VERSION ""

NS_ :

BS_:

BU_: XXX DSU HCU EPS IPAS

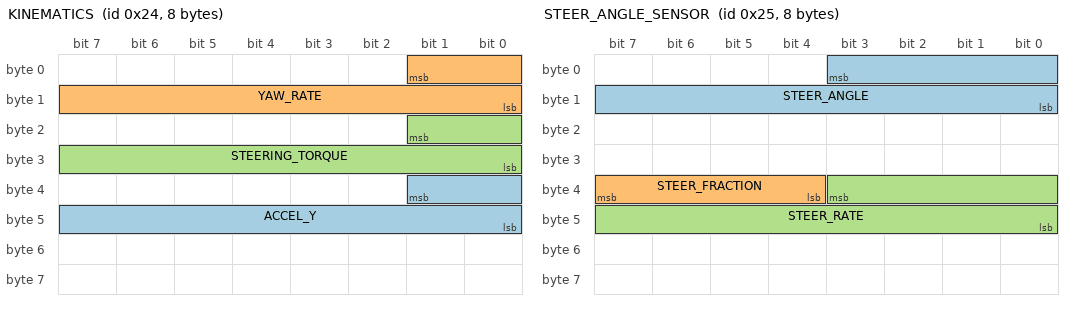
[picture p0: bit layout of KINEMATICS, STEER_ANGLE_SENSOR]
BO_ 36 KINEMATICS: 8 XXX
 SG_ ACCEL_Y : 33|10@0+ (1,-512) [0|65535] "" XXX
 SG_ YAW_RATE : 1|10@0+ (1,-512) [0|65535] "" XXX
 SG_ STEERING_TORQUE : 17|10@0+ (1,-512) [0|65535] "" XXX

BO_ 37 STEER_ANGLE_SENSOR: 8 XXX
 SG_ STEER_ANGLE : 3|12@0- (1.5,0) [-500|500] "deg" XXX
 SG_ STEER_FRACTION : 39|4@0- (0.1,0) [-0.7|0.7] "deg" XXX
 SG_ STEER_RATE : 35|12@0- (1,0) [-2000|2000] "deg/s" XXX

BO_ 166 BRAKE: 8 XXX
 SG_ BRAKE_AMOUNT : 7|8@0+ (1,0) [0|255] "" XXX
 SG_ BRAKE_PEDAL : 23|8@0+ (1,0) [0|255] "" XXX

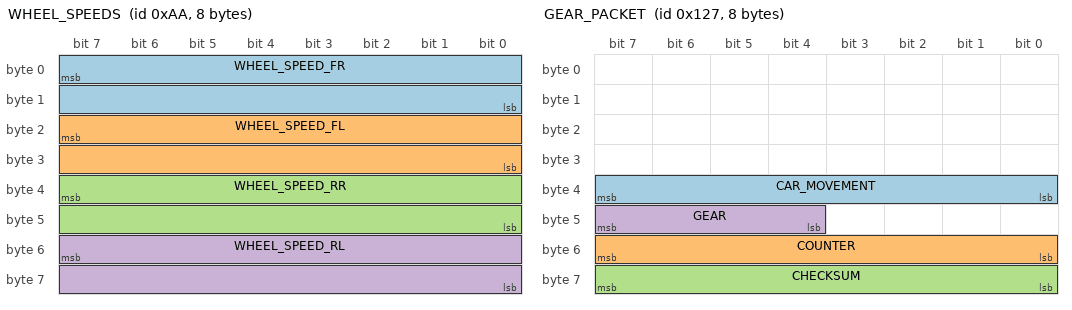
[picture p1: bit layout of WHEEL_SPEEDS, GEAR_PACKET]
BO_ 170 WHEEL_SPEEDS: 8 XXX
 SG_ WHEEL_SPEED_FR : 7|16@0+ (0.01,-67.67) [0|250] "kph" XXX
 SG_ WHEEL_SPEED_FL : 23|16@0+ (0.01,-67.67) [0|250] "kph" XXX
 SG_ WHEEL_SPEED_RR : 39|16@0+ (0.01,-67.67) [0|250] "kph" XXX
 SG_ WHEEL_SPEED_RL : 55|16@0+ (0.01,-67.67) [0|250] "kph" XXX

BO_ 176 WHEEL_SPEED_1: 8 XXX
 SG_ NEW_SIGNAL_3 : 43|4@0+ (1,0) [0|15] "" XXX
 SG_ wheel_1 : 7|16@0+ (1,0) [0|1] "" XXX
 SG_ wheel_2 : 23|16@0+ (1,0) [0|3] "" XXX

BO_ 178 WHEEL_SPEED_2: 8 XXX
 SG_ NEW_SIGNAL_3 : 47|8@0+ (1,0) [0|65535] "" XXX
 SG_ WHEEL_3 : 7|16@0+ (1,0) [0|65535] "" XXX
 SG_ wheel_4 : 23|16@0+ (1,0) [0|65535] "" XXX

BO_ 180 SPEED: 8 XXX
 SG_ CHECKSUM : 63|8@0+ (1,0) [0|255] "" XXX
 SG_ ENCODER : 39|8@0+ (1,0) [0|255] "" XXX
 SG_ SPEED : 47|16@0+ (0.01,0) [0|250] "kph" XXX

BO_ 295 GEAR_PACKET: 8 XXX
 SG_ CAR_MOVEMENT : 39|8@0- (1,0) [0|255] "" XXX
 SG_ COUNTER : 55|8@0+ (1,0) [0|255] "" XXX
 SG_ CHECKSUM : 63|8@0+ (1,0) [0|255] "" XXX
 SG_ GEAR : 47|4@0+ (1,0) [0|15] "" XXX

BO_ 466 PCM_CRUISE: 8 XXX
 SG_ GAS_RELEASED : 4|1@0+ (1,0) [0|1] "" XXX
 SG_ CRUISE_STATE : 55|4@0+ (1,0) [0|15] "" XXX

BO_ 467 PCM_CRUISE_2: 8 XXX
 SG_ MAIN_ON : 15|1@0+ (1,0) [0|1] "" XXX
 SG_ SET_SPEED : 23|8@0+ (1,0) [0|255] "kph" XXX

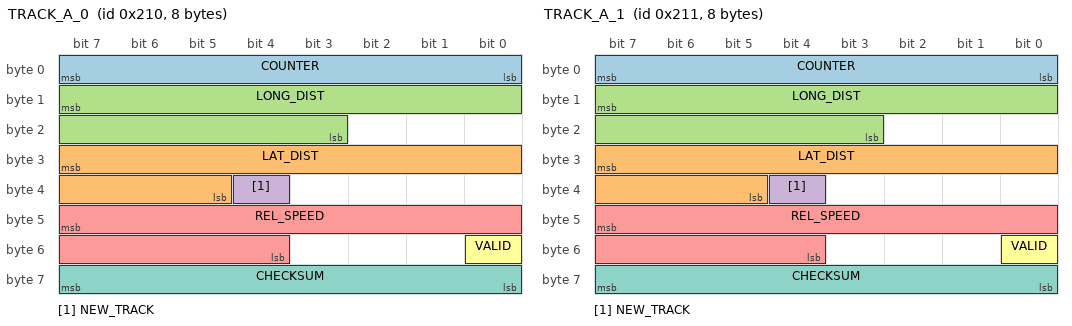
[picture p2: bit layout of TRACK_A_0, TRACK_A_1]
BO_ 528 TRACK_A_0: 8 XXX
 SG_ COUNTER : 7|8@0+ (1,0) [0|255] "" XXX
 SG_ LAT_DIST : 31|11@0- (0.04,0) [-50|50] "m" XXX
 SG_ LONG_DIST : 15|13@0+ (0.04,0) [0|300] "m" XXX
 SG_ NEW_TRACK : 36|1@0+ (1,0) [0|1] "" XXX
 SG_ REL_SPEED : 47|12@0- (0.025,0) [-100|100] "m/s" XXX
 SG_ VALID : 48|1@0+ (1,0) [0|1] "" XXX
 SG_ CHECKSUM : 63|8@0+ (1,0) [0|255] "" XXX

BO_ 529 TRACK_A_1: 8 XXX
 SG_ COUNTER : 7|8@0+ (1,0) [0|255] "" XXX
 SG_ LAT_DIST : 31|11@0- (0.04,0) [-50|50] "m" XXX
 SG_ LONG_DIST : 15|13@0+ (0.04,0) [0|300] "m" XXX
 SG_ NEW_TRACK : 36|1@0+ (1,0) [0|1] "" XXX
 SG_ REL_SPEED : 47|12@0- (0.025,0) [-100|100] "m/s" XXX
 SG_ VALID : 48|1@0+ (1,0) [0|1] "" XXX
 SG_ CHECKSUM : 63|8@0+ (1,0) [0|255] "" XXX

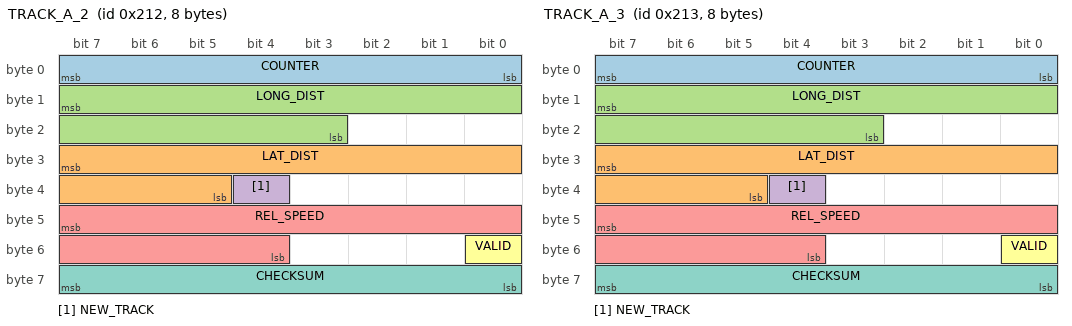
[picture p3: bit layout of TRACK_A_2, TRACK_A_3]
BO_ 530 TRACK_A_2: 8 XXX
 SG_ COUNTER : 7|8@0+ (1,0) [0|255] "" XXX
 SG_ LAT_DIST : 31|11@0- (0.04,0) [-50|50] "m" XXX
 SG_ LONG_DIST : 15|13@0+ (0.04,0) [0|300] "m" XXX
 SG_ NEW_TRACK : 36|1@0+ (1,0) [0|1] "" XXX
 SG_ REL_SPEED : 47|12@0- (0.025,0) [-100|100] "m/s" XXX
 SG_ VALID : 48|1@0+ (1,0) [0|1] "" XXX
 SG_ CHECKSUM : 63|8@0+ (1,0) [0|255] "" XXX

BO_ 531 TRACK_A_3: 8 XXX
 SG_ COUNTER : 7|8@0+ (1,0) [0|255] "" XXX
 SG_ LAT_DIST : 31|11@0- (0.04,0) [-50|50] "m" XXX
 SG_ LONG_DIST : 15|13@0+ (0.04,0) [0|300] "m" XXX
 SG_ NEW_TRACK : 36|1@0+ (1,0) [0|1] "" XXX
 SG_ REL_SPEED : 47|12@0- (0.025,0) [-100|100] "m/s" XXX
 SG_ VALID : 48|1@0+ (1,0) [0|1] "" XXX
 SG_ CHECKSUM : 63|8@0+ (1,0) [0|255] "" XXX

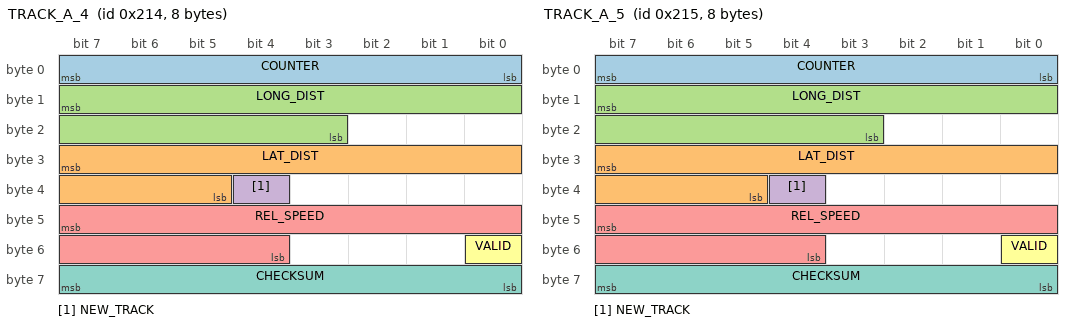
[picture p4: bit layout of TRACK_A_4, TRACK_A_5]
BO_ 532 TRACK_A_4: 8 XXX
 SG_ COUNTER : 7|8@0+ (1,0) [0|255] "" XXX
 SG_ LAT_DIST : 31|11@0- (0.04,0) [-50|50] "m" XXX
 SG_ LONG_DIST : 15|13@0+ (0.04,0) [0|300] "m" XXX
 SG_ NEW_TRACK : 36|1@0+ (1,0) [0|1] "" XXX
 SG_ REL_SPEED : 47|12@0- (0.025,0) [-100|100] "m/s" XXX
 SG_ VALID : 48|1@0+ (1,0) [0|1] "" XXX
 SG_ CHECKSUM : 63|8@0+ (1,0) [0|255] "" XXX

BO_ 533 TRACK_A_5: 8 XXX
 SG_ COUNTER : 7|8@0+ (1,0) [0|255] "" XXX
 SG_ LAT_DIST : 31|11@0- (0.04,0) [-50|50] "m" XXX
 SG_ LONG_DIST : 15|13@0+ (0.04,0) [0|300] "m" XXX
 SG_ NEW_TRACK : 36|1@0+ (1,0) [0|1] "" XXX
 SG_ REL_SPEED : 47|12@0- (0.025,0) [-100|100] "m/s" XXX
 SG_ VALID : 48|1@0+ (1,0) [0|1] "" XXX
 SG_ CHECKSUM : 63|8@0+ (1,0) [0|255] "" XXX

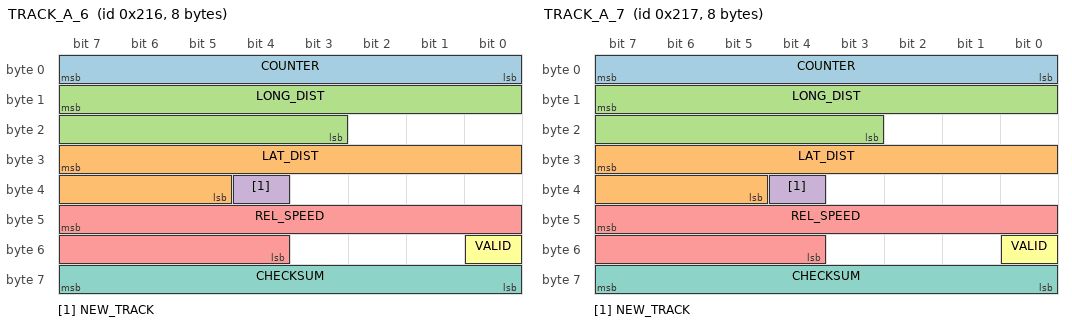
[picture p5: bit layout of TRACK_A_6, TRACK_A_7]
BO_ 534 TRACK_A_6: 8 XXX
 SG_ COUNTER : 7|8@0+ (1,0) [0|255] "" XXX
 SG_ LAT_DIST : 31|11@0- (0.04,0) [-50|50] "m" XXX
 SG_ LONG_DIST : 15|13@0+ (0.04,0) [0|300] "m" XXX
 SG_ NEW_TRACK : 36|1@0+ (1,0) [0|1] "" XXX
 SG_ REL_SPEED : 47|12@0- (0.025,0) [-100|100] "m/s" XXX
 SG_ VALID : 48|1@0+ (1,0) [0|1] "" XXX
 SG_ CHECKSUM : 63|8@0+ (1,0) [0|255] "" XXX

BO_ 535 TRACK_A_7: 8 XXX
 SG_ COUNTER : 7|8@0+ (1,0) [0|255] "" XXX
 SG_ LAT_DIST : 31|11@0- (0.04,0) [-50|50] "m" XXX
 SG_ LONG_DIST : 15|13@0+ (0.04,0) [0|300] "m" XXX
 SG_ NEW_TRACK : 36|1@0+ (1,0) [0|1] "" XXX
 SG_ REL_SPEED : 47|12@0- (0.025,0) [-100|100] "m/s" XXX
 SG_ VALID : 48|1@0+ (1,0) [0|1] "" XXX
 SG_ CHECKSUM : 63|8@0+ (1,0) [0|255] "" XXX

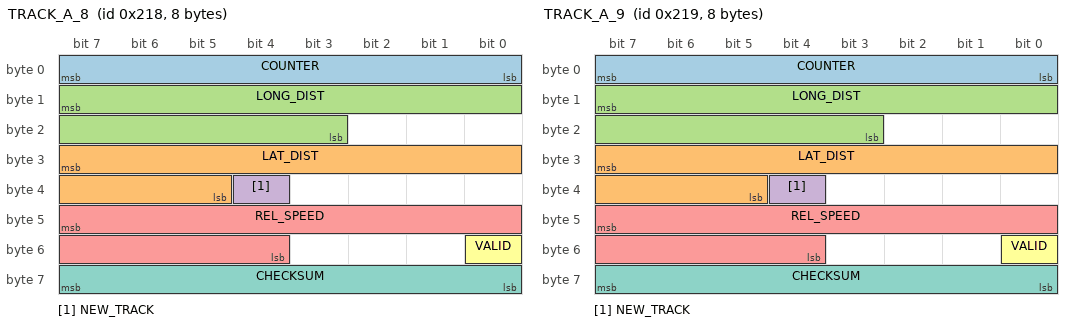
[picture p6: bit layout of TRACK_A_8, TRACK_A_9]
BO_ 536 TRACK_A_8: 8 XXX
 SG_ COUNTER : 7|8@0+ (1,0) [0|255] "" XXX
 SG_ LAT_DIST : 31|11@0- (0.04,0) [-50|50] "m" XXX
 SG_ LONG_DIST : 15|13@0+ (0.04,0) [0|300] "m" XXX
 SG_ NEW_TRACK : 36|1@0+ (1,0) [0|1] "" XXX
 SG_ REL_SPEED : 47|12@0- (0.025,0) [-100|100] "m/s" XXX
 SG_ VALID : 48|1@0+ (1,0) [0|1] "" XXX
 SG_ CHECKSUM : 63|8@0+ (1,0) [0|255] "" XXX

BO_ 537 TRACK_A_9: 8 XXX
 SG_ COUNTER : 7|8@0+ (1,0) [0|255] "" XXX
 SG_ LAT_DIST : 31|11@0- (0.04,0) [-50|50] "m" XXX
 SG_ LONG_DIST : 15|13@0+ (0.04,0) [0|300] "m" XXX
 SG_ NEW_TRACK : 36|1@0+ (1,0) [0|1] "" XXX
 SG_ REL_SPEED : 47|12@0- (0.025,0) [-100|100] "m/s" XXX
 SG_ VALID : 48|1@0+ (1,0) [0|1] "" XXX
 SG_ CHECKSUM : 63|8@0+ (1,0) [0|255] "" XXX

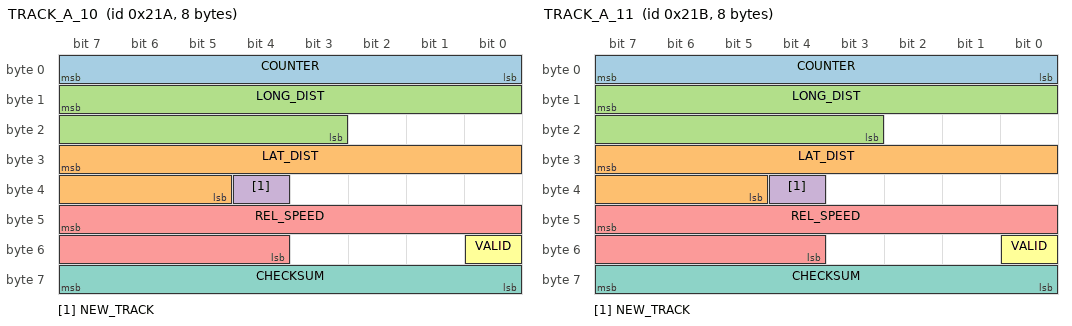
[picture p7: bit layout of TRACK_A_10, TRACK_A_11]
BO_ 538 TRACK_A_10: 8 XXX
 SG_ COUNTER : 7|8@0+ (1,0) [0|255] "" XXX
 SG_ LAT_DIST : 31|11@0- (0.04,0) [-50|50] "m" XXX
 SG_ LONG_DIST : 15|13@0+ (0.04,0) [0|300] "m" XXX
 SG_ NEW_TRACK : 36|1@0+ (1,0) [0|1] "" XXX
 SG_ REL_SPEED : 47|12@0- (0.025,0) [-100|100] "m/s" XXX
 SG_ VALID : 48|1@0+ (1,0) [0|1] "" XXX
 SG_ CHECKSUM : 63|8@0+ (1,0) [0|255] "" XXX

BO_ 539 TRACK_A_11: 8 XXX
 SG_ COUNTER : 7|8@0+ (1,0) [0|255] "" XXX
 SG_ LAT_DIST : 31|11@0- (0.04,0) [-50|50] "m" XXX
 SG_ LONG_DIST : 15|13@0+ (0.04,0) [0|300] "m" XXX
 SG_ NEW_TRACK : 36|1@0+ (1,0) [0|1] "" XXX
 SG_ REL_SPEED : 47|12@0- (0.025,0) [-100|100] "m/s" XXX
 SG_ VALID : 48|1@0+ (1,0) [0|1] "" XXX
 SG_ CHECKSUM : 63|8@0+ (1,0) [0|255] "" XXX

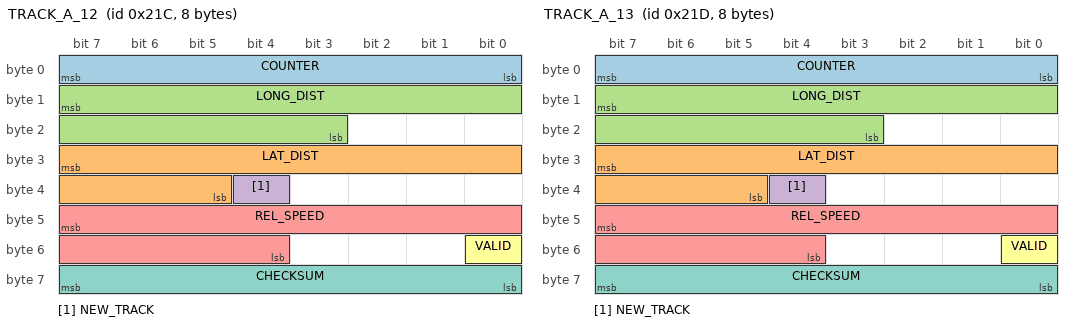
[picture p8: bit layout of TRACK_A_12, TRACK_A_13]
BO_ 540 TRACK_A_12: 8 XXX
 SG_ COUNTER : 7|8@0+ (1,0) [0|255] "" XXX
 SG_ LAT_DIST : 31|11@0- (0.04,0) [-50|50] "m" XXX
 SG_ LONG_DIST : 15|13@0+ (0.04,0) [0|300] "m" XXX
 SG_ NEW_TRACK : 36|1@0+ (1,0) [0|1] "" XXX
 SG_ REL_SPEED : 47|12@0- (0.025,0) [-100|100] "m/s" XXX
 SG_ VALID : 48|1@0+ (1,0) [0|1] "" XXX
 SG_ CHECKSUM : 63|8@0+ (1,0) [0|255] "" XXX

BO_ 541 TRACK_A_13: 8 XXX
 SG_ COUNTER : 7|8@0+ (1,0) [0|255] "" XXX
 SG_ LAT_DIST : 31|11@0- (0.04,0) [-50|50] "m" XXX
 SG_ LONG_DIST : 15|13@0+ (0.04,0) [0|300] "m" XXX
 SG_ NEW_TRACK : 36|1@0+ (1,0) [0|1] "" XXX
 SG_ REL_SPEED : 47|12@0- (0.025,0) [-100|100] "m/s" XXX
 SG_ VALID : 48|1@0+ (1,0) [0|1] "" XXX
 SG_ CHECKSUM : 63|8@0+ (1,0) [0|255] "" XXX

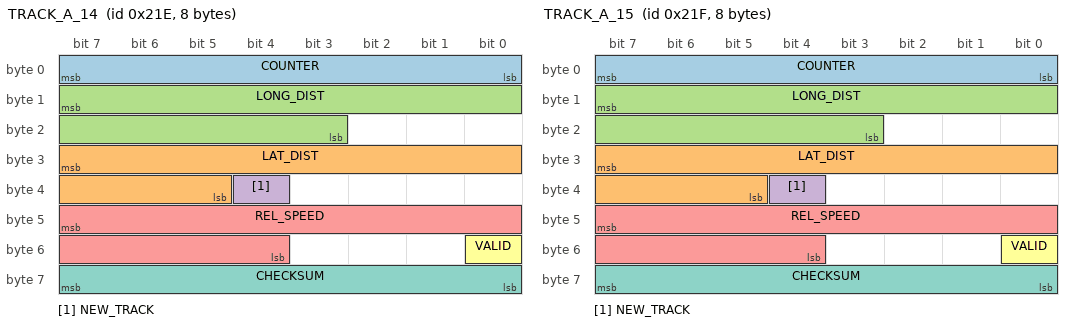
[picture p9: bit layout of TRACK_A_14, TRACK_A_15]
BO_ 542 TRACK_A_14: 8 XXX
 SG_ COUNTER : 7|8@0+ (1,0) [0|255] "" XXX
 SG_ LAT_DIST : 31|11@0- (0.04,0) [-50|50] "m" XXX
 SG_ LONG_DIST : 15|13@0+ (0.04,0) [0|300] "m" XXX
 SG_ NEW_TRACK : 36|1@0+ (1,0) [0|1] "" XXX
 SG_ REL_SPEED : 47|12@0- (0.025,0) [-100|100] "m/s" XXX
 SG_ VALID : 48|1@0+ (1,0) [0|1] "" XXX
 SG_ CHECKSUM : 63|8@0+ (1,0) [0|255] "" XXX

BO_ 543 TRACK_A_15: 8 XXX
 SG_ COUNTER : 7|8@0+ (1,0) [0|255] "" XXX
 SG_ LAT_DIST : 31|11@0- (0.04,0) [-50|50] "m" XXX
 SG_ LONG_DIST : 15|13@0+ (0.04,0) [0|300] "m" XXX
 SG_ NEW_TRACK : 36|1@0+ (1,0) [0|1] "" XXX
 SG_ REL_SPEED : 47|12@0- (0.025,0) [-100|100] "m/s" XXX
 SG_ VALID : 48|1@0+ (1,0) [0|1] "" XXX
 SG_ CHECKSUM : 63|8@0+ (1,0) [0|255] "" XXX

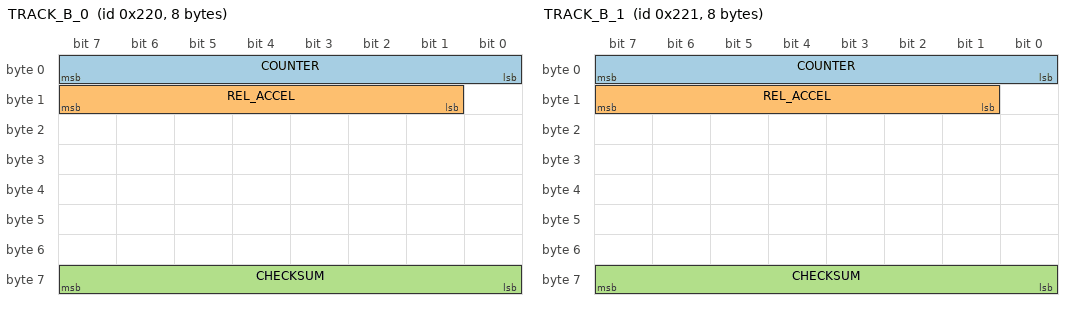
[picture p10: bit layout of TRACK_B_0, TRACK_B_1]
BO_ 544 TRACK_B_0: 8 XXX
 SG_ COUNTER : 7|8@0+ (1,0) [0|255] "" XXX
 SG_ REL_ACCEL : 15|7@0- (1,0) [-64|63] "" XXX
 SG_ CHECKSUM : 63|8@0+ (1,0) [0|255] "" XXX

BO_ 545 TRACK_B_1: 8 XXX
 SG_ COUNTER : 7|8@0+ (1,0) [0|255] "" XXX
 SG_ REL_ACCEL : 15|7@0- (1,0) [-64|63] "" XXX
 SG_ CHECKSUM : 63|8@0+ (1,0) [0|255] "" XXX

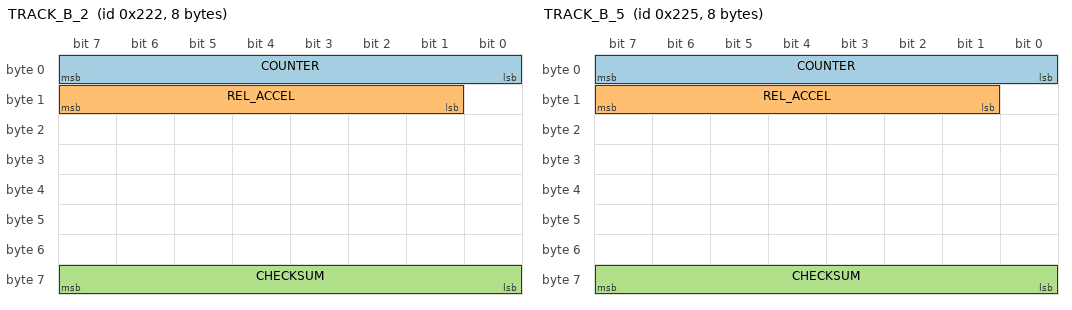
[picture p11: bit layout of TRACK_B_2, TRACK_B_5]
BO_ 546 TRACK_B_2: 8 XXX
 SG_ COUNTER : 7|8@0+ (1,0) [0|255] "" XXX
 SG_ REL_ACCEL : 15|7@0- (1,0) [-64|63] "" XXX
 SG_ CHECKSUM : 63|8@0+ (1,0) [0|255] "" XXX

BO_ 547 TRACK_B_3: 8 XXX
 SG_ COUNTER : 7|8@0+ (1,0) [0|255] "" XXX
 SG_ CHECKSUM : 63|8@0+ (1,0) [0|255] "" XXX

BO_ 548 BRAKE_LIGHT: 8 XXX
 SG_ ON_OFF : 7|8@0+ (1,0) [0|255] "" XXX

BO_ 549 TRACK_B_5: 8 XXX
 SG_ COUNTER : 7|8@0+ (1,0) [0|255] "" XXX
 SG_ REL_ACCEL : 15|7@0- (1,0) [-64|63] "" XXX
 SG_ CHECKSUM : 63|8@0+ (1,0) [0|255] "" XXX

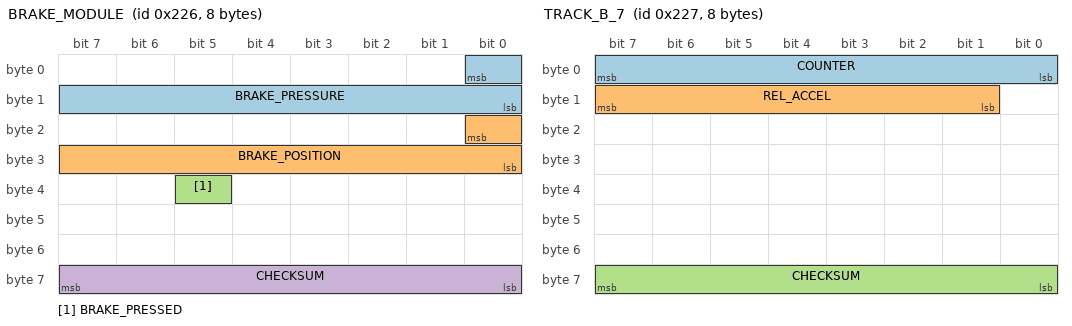
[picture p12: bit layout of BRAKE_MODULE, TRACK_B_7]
BO_ 550 BRAKE_MODULE: 8 XXX
 SG_ BRAKE_PRESSURE : 0|9@0+ (1,0) [0|511] "" XXX
 SG_ BRAKE_POSITION : 16|9@0+ (1,0) [0|511] "" XXX
 SG_ BRAKE_PRESSED : 37|1@0+ (1,0) [0|1] "" XXX
 SG_ CHECKSUM : 63|8@0+ (1,0) [0|255] "" XXX

BO_ 551 TRACK_B_7: 8 XXX
 SG_ COUNTER : 7|8@0+ (1,0) [0|255] "" XXX
 SG_ REL_ACCEL : 15|7@0- (1,0) [-64|63] "" XXX
 SG_ CHECKSUM : 63|8@0+ (1,0) [0|255] "" XXX

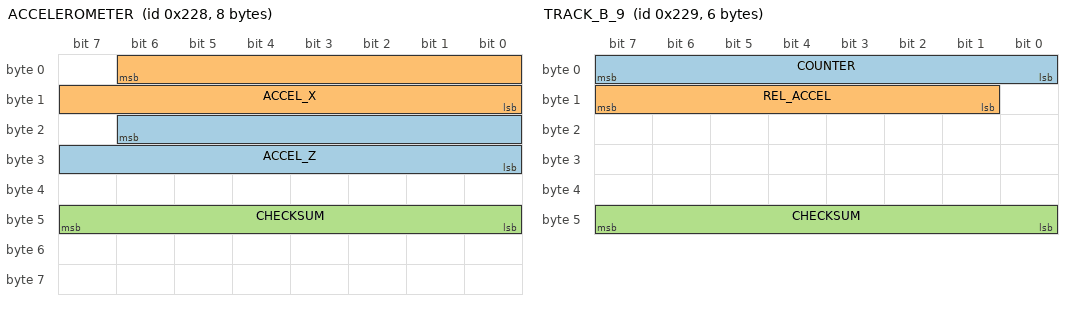
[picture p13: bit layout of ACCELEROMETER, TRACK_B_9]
BO_ 552 ACCELEROMETER: 8 XXX
 SG_ ACCEL_Z : 22|15@0- (1,0) [0|32767] "" XXX
 SG_ ACCEL_X : 6|15@0- (0.001,0) [-20|20] "m/s2" XXX
 SG_ CHECKSUM : 47|8@0+ (1,0) [0|255] "" XXX

BO_ 553 TRACK_B_9: 6 XXX
 SG_ COUNTER : 7|8@0+ (1,0) [0|255] "" XXX
 SG_ REL_ACCEL : 15|7@0- (1,0) [-64|63] "" XXX
 SG_ CHECKSUM : 47|8@0+ (1,0) [0|255] "" XXX

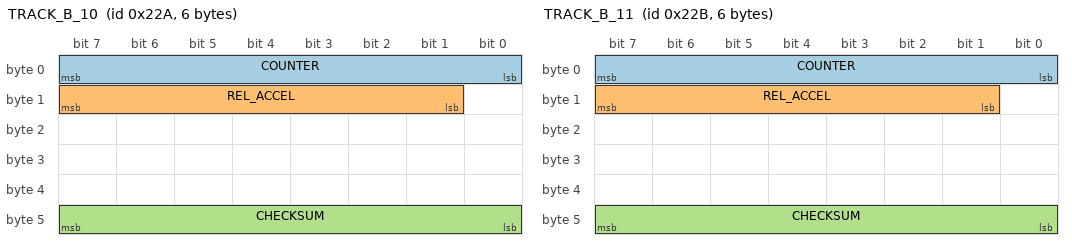
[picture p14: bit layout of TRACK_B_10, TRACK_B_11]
BO_ 554 TRACK_B_10: 6 XXX
 SG_ COUNTER : 7|8@0+ (1,0) [0|255] "" XXX
 SG_ REL_ACCEL : 15|7@0- (1,0) [-64|63] "" XXX
 SG_ CHECKSUM : 47|8@0+ (1,0) [0|255] "" XXX

BO_ 555 TRACK_B_11: 6 XXX
 SG_ COUNTER : 7|8@0+ (1,0) [0|255] "" XXX
 SG_ REL_ACCEL : 15|7@0- (1,0) [-64|63] "" XXX
 SG_ CHECKSUM : 47|8@0+ (1,0) [0|255] "" XXX

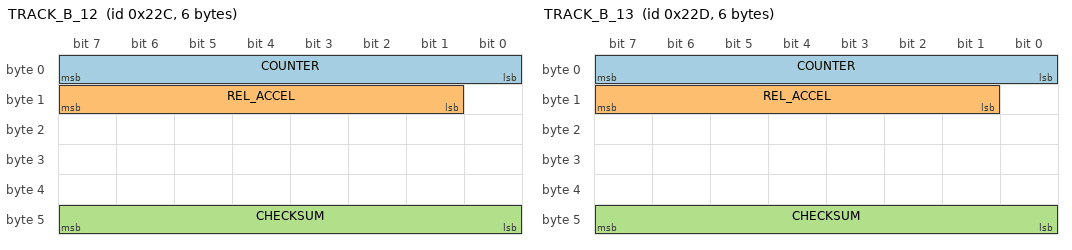
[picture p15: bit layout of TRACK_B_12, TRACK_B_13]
BO_ 556 TRACK_B_12: 6 XXX
 SG_ COUNTER : 7|8@0+ (1,0) [0|255] "" XXX
 SG_ REL_ACCEL : 15|7@0- (1,0) [-64|63] "" XXX
 SG_ CHECKSUM : 47|8@0+ (1,0) [0|255] "" XXX

BO_ 557 TRACK_B_13: 6 XXX
 SG_ COUNTER : 7|8@0+ (1,0) [0|255] "" XXX
 SG_ REL_ACCEL : 15|7@0- (1,0) [-64|63] "" XXX
 SG_ CHECKSUM : 47|8@0+ (1,0) [0|255] "" XXX

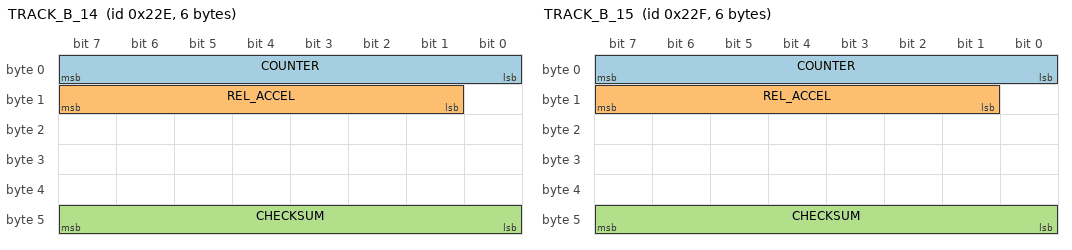
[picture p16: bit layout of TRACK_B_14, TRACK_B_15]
BO_ 558 TRACK_B_14: 6 XXX
 SG_ COUNTER : 7|8@0+ (1,0) [0|255] "" XXX
 SG_ REL_ACCEL : 15|7@0- (1,0) [-64|63] "" XXX
 SG_ CHECKSUM : 47|8@0+ (1,0) [0|255] "" XXX

BO_ 559 TRACK_B_15: 6 XXX
 SG_ COUNTER : 7|8@0+ (1,0) [0|255] "" XXX
 SG_ REL_ACCEL : 15|7@0- (1,0) [-64|63] "" XXX
 SG_ CHECKSUM : 47|8@0+ (1,0) [0|255] "" XXX

BO_ 560 BRAKE_MODULE2: 8 XXX
 SG_ BRAKE_LIGHTS : 26|1@0+ (1,0) [0|1] "" XXX

BO_ 581 GAS_PEDAL: 8 XXX
 SG_ GAS_PEDAL : 23|8@0+ (0.005,0) [0|1] "" XXX

BO_ 608 STEER_TORQUE_SENSOR: 8 XXX
 SG_ STEER_TORQUE_EPS : 47|16@0- (0.5,0) [0|65535] "" XXX
 SG_ STEER_TORQUE_DRIVER : 15|16@0- (1,0) [-32768|32767] "" XXX
 SG_ STEER_OVERRIDE : 0|1@0+ (1,0) [0|1] "" XXX

BO_ 610 EPS_STATUS: 8 EPS
 SG_ STATE : 3|4@0+ (1,0) [0|15] "" XXX

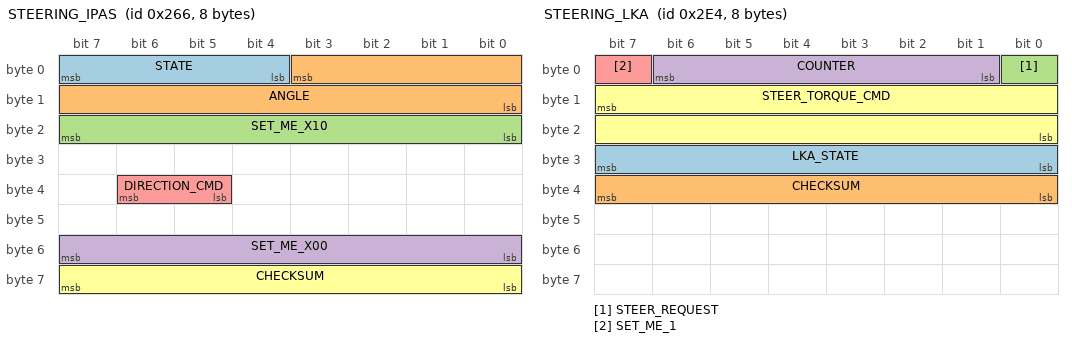
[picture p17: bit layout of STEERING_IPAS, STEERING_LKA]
BO_ 614 STEERING_IPAS: 8 IPAS
 SG_ STATE : 7|4@0+ (1,0) [0|15] "" XXX
 SG_ ANGLE : 3|12@0- (1,0) [0|16777215] "" XXX
 SG_ SET_ME_X10 : 23|8@0+ (1,0) [0|255] "" XXX
 SG_ SET_ME_X00 : 55|8@0+ (1,0) [0|255] "" XXX
 SG_ DIRECTION_CMD : 38|2@0+ (1,0) [0|3] "" XXX
 SG_ CHECKSUM : 63|8@0+ (1,0) [0|255] "" XXX

BO_ 643 PRE_COLLISION: 8 XXX

BO_ 740 STEERING_LKA: 8 XXX
 SG_ LKA_STATE : 31|8@0+ (1,0) [0|255] "" XXX
 SG_ CHECKSUM : 39|8@0+ (1,0) [0|255] "" XXX
 SG_ STEER_REQUEST : 0|1@0+ (1,0) [0|1] "" XXX
 SG_ COUNTER : 6|6@0+ (1,0) [0|63] "" XXX
 SG_ SET_ME_1 : 7|1@0+ (1,0) [0|1] "" XXX
 SG_ STEER_TORQUE_CMD : 15|16@0- (1,0) [0|65535] "" XXX

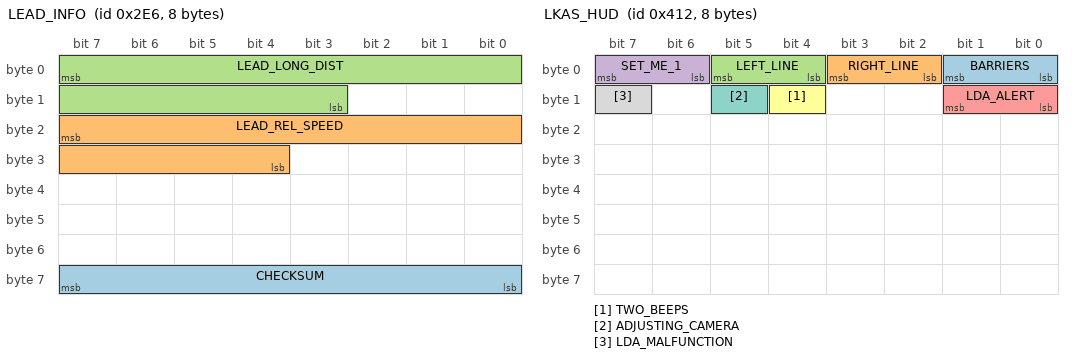
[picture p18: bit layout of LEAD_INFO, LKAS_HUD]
BO_ 742 LEAD_INFO: 8 DSU
 SG_ CHECKSUM : 63|8@0+ (1,0) [0|255] "" HCU
 SG_ LEAD_REL_SPEED : 23|12@0- (0.025,0) [-100|100] "m/s" HCU
 SG_ LEAD_LONG_DIST : 7|13@0+ (0.05,0) [0|300] "m" HCU

BO_ 835 ACC_CONTROL: 8 DSU
 SG_ ACCEL_CMD : 7|16@0- (0.001,0) [-20|20] "m/s2" HCU

BO_ 921 PCM_CRUISE_SM: 8 XXX
 SG_ MAIN_ON : 4|1@0+ (1,0) [0|1] "" XXX
 SG_ CRUISE_CONTROL_STATE : 11|4@0+ (1,0) [0|15] "" XXX

BO_ 951 ESP_CONTROL: 8 ESP
 SG_ TC_DISABLED : 13|1@0+ (1,0) [0|1] "" XXX

BO_ 1042 LKAS_HUD: 8 XXX
 SG_ BARRIERS : 1|2@0+ (1,0) [0|3] "" XXX
 SG_ RIGHT_LINE : 3|2@0+ (1,0) [0|3] "" XXX
 SG_ LEFT_LINE : 5|2@0+ (1,0) [0|3] "" XXX
 SG_ SET_ME_1 : 7|2@0+ (1,0) [0|3] "" XXX
 SG_ LDA_ALERT : 9|2@0+ (1,0) [0|3] "" XXX
 SG_ TWO_BEEPS : 12|1@0+ (1,0) [0|1] "" XXX
 SG_ ADJUSTING_CAMERA : 13|1@0+ (1,0) [0|1] "" XXX
 SG_ LDA_MALFUNCTION : 15|1@0+ (1,0) [0|1] "" XXX

BO_ 1556 STEERING_LEVERS: 8 XXX
 SG_ TURN_SIGNALS : 29|2@0+ (1,0) [0|3] "" XXX

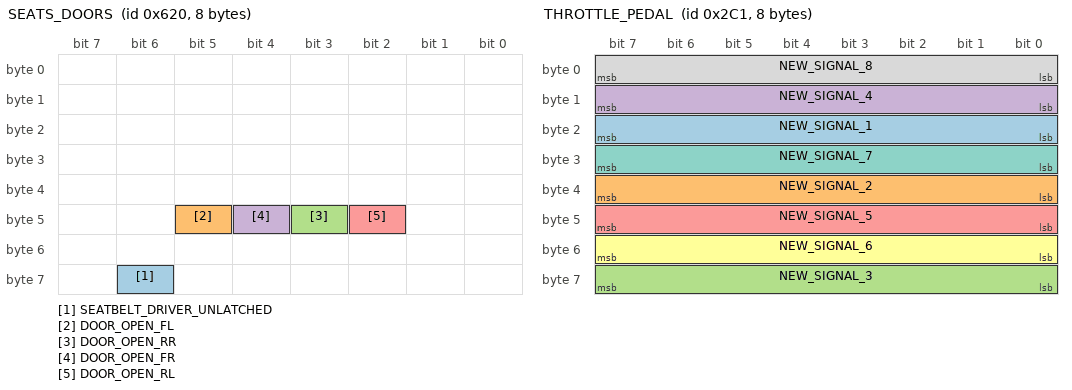
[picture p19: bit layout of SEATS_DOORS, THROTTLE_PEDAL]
BO_ 1568 SEATS_DOORS: 8 XXX
 SG_ SEATBELT_DRIVER_UNLATCHED : 62|1@0+ (1,0) [0|1] "" XXX
 SG_ DOOR_OPEN_FL : 45|1@0+ (1,0) [0|1] "" XXX
 SG_ DOOR_OPEN_RR : 43|1@0+ (1,0) [0|1] "" XXX
 SG_ DOOR_OPEN_FR : 44|1@0+ (1,0) [0|1] "" XXX
 SG_ DOOR_OPEN_RL : 42|1@0+ (1,0) [0|1] "" XXX

BO_ 186 MSG_0xBA: 8 XXX

BO_ 562 MSG_0x232: 8 XXX
 SG_ NEW_SIGNAL_1 : 7|8@0+ (1,0) [0|255] "" XXX
 SG_ NEW_SIGNAL_2 : 15|8@0+ (1,0) [0|255] "" XXX
 SG_ NEW_SIGNAL_4 : 31|8@0+ (1,0) [0|255] "" XXX

BO_ 708 ENGINE_SPEED: 8 XXX
 SG_ NEW_SIGNAL_1 : 15|8@0+ (1,0) [0|255] "" XXX
 SG_ NEW_SIGNAL_2 : 63|8@0+ (1,0) [0|255] "" XXX

BO_ 948 MONO_INCR: 8 XXX
 SG_ NEW_SIGNAL_1 : 23|8@0+ (1,0) [0|255] "" XXX

BO_ 920 UNLIKELY_FUEL: 8 XXX
 SG_ NEW_SIGNAL_1 : 7|16@0+ (1,0) [0|65535] "" XXX

BO_ 705 THROTTLE_PEDAL: 8 XXX
 SG_ NEW_SIGNAL_1 : 23|8@0+ (1,0) [0|255] "" XXX
 SG_ NEW_SIGNAL_2 : 39|8@0+ (1,0) [0|255] "" XXX
 SG_ NEW_SIGNAL_3 : 63|8@0+ (1,0) [0|255] "" XXX
 SG_ NEW_SIGNAL_4 : 15|8@0+ (1,0) [0|255] "" XXX
 SG_ NEW_SIGNAL_5 : 47|8@0+ (1,0) [0|255] "" XXX
 SG_ NEW_SIGNAL_6 : 55|8@0+ (1,0) [0|255] "" XXX
 SG_ NEW_SIGNAL_7 : 31|8@0+ (1,0) [0|255] "" XXX
 SG_ NEW_SIGNAL_8 : 7|8@0+ (1,0) [0|255] "" XXX

BO_ 1600 0x640: 8 XXX
 SG_ NEW_SIGNAL_1 : 47|8@0+ (1,0) [0|255] "" XXX

BO_ 1592 638: 8 XXX
 SG_ NEW_SIGNAL_1 : 7|8@0+ (1,0) [0|255] "" XXX

BO_ 1584 630: 8 XXX
 SG_ NEW_SIGNAL_1 : 7|8@0+ (1,0) [0|255] "" XXX

BO_ 1572 624: 8 XXX

BO_ 1570 622: 8 XXX
 SG_ NEW_SIGNAL_1 : 7|8@0+ (1,0) [0|255] "" XXX

BO_ 1569 621: 8 XXX
 SG_ NEW_SIGNAL_1 : 7|8@0+ (1,0) [0|255] "" XXX

BO_ 1553 611: 8 XXX

BO_ 1245 4dd: 8 XXX

BO_ 1244 4dc: 8 XXX

BO_ 1224 4c8: 8 XXX

BO_ 1219 4c3: 8 XXX

BO_ 1217 4c1: 8 XXX

BO_ 720 2d0: 8 XXX
 SG_ NEW_SIGNAL_1 : 15|8@0+ (1,0) [0|255] "" XXX
 SG_ NEW_SIGNAL_2 : 63|8@0+ (1,0) [0|255] "" XXX

BO_ 928 3a0: 8 XXX
 SG_ NEW_SIGNAL_1 : 63|8@0+ (1,0) [0|255] "" XXX

BO_ 1088 440: 8 XXX
 SG_ NEW_SIGNAL_1 : 7|16@0+ (1,0) [0|65535] "" XXX

BO_ 1090 442: 8 XXX
 SG_ NEW_SIGNAL_1 : 7|16@0+ (1,0) [0|65535] "" XXX

BO_ 916 394: 8 XXX

BO_ 947 ENGINE_SPEED_2: 8 XXX
 SG_ NEW_SIGNAL_1 : 7|16@0+ (1,0) [0|255] "" XXX
 SG_ NEW_SIGNAL_3 : 23|8@0+ (1,0) [0|255] "" XXX

BO_ 1552 SPEED_2: 8 XXX
 SG_ NEW_SIGNAL_1 : 23|8@0+ (1,0) [0|255] "" XXX

BO_ 896 380: 8 XXX

BO_ 906 38a: 8 XXX

BO_ 929 3a1: 8 XXX

BO_ 944 3b0: 8 XXX
 SG_ NEW_SIGNAL_1 : 31|8@0+ (1,0) [0|255] "" XXX

BO_ 945 3b1: 8 XXX
 SG_ NEW_SIGNAL_1 : 31|8@0+ (1,0) [0|255] "" XXX

CM_ SG_ 36 ACCEL_Y "unit is tbd";
CM_ SG_ 36 YAW_RATE "verify";
CM_ SG_ 36 STEERING_TORQUE "does not seem the steer torque, tbd";
CM_ SG_ 37 STEER_FRACTION "1/15th of the signal STEER_ANGLE, which is 1.5 deg; note that 0x8 is never set";
CM_ SG_ 37 STEER_RATE "factor is tbd";
CM_ SG_ 176 NEW_SIGNAL_3 "0x1100-0x110F repeated";
CM_ SG_ 178 NEW_SIGNAL_3 "0x1100-0x110f repeated";
CM_ SG_ 467 SET_SPEED "43 kph are shown as 28mph, so conversion isnt perfect";
CM_ SG_ 550 BRAKE_PRESSURE "seems prop to pedal force";
CM_ SG_ 550 BRAKE_POSITION "seems proportional to pedal displacement, unclear the max value of 0x1c8";
CM_ SG_ 560 BRAKE_LIGHTS "double check";
CM_ SG_ 581 GAS_PEDAL "it seems slightly filtered";
CM_ SG_ 608 STEER_TORQUE_EPS "0.5 factor to be comparable with STEER_TORQUE_CMD";
CM_ SG_ 608 STEER_TORQUE_DRIVER "driver torque";
CM_ SG_ 608 STEER_OVERRIDE "set when driver torque exceeds a certain value";
CM_ SG_ 614 ANGLE "set to measured angle when ipas control isn't active";
CM_ SG_ 1042 SET_ME_1 "unclear what this is, nut it's always 1 in drive traces";
CM_ SG_ 705 NEW_SIGNAL_3 "0x0801??01??ca00??";
CM_ SG_ 720 NEW_SIGNAL_2 "0xd??1000720003??";
VAL_ 295 GEAR 0 "P" 1 "R" 2 "N" 3 "D" 4 "B" ;
VAL_ 466 CRUISE_STATE 8 "active" 7 "standstill" 1 "off" ;
VAL_ 610 STATE 5 "override" 3 "enabled" 1 "disabled" ;
VAL_ 614 STATE 3 "enabled" 1 "disabled" ;
VAL_ 614 DIRECTION_CMD 3 "right" 2 "center" 1 "left" ;
VAL_ 921 CRUISE_CONTROL_STATE 2 "disabled" 11 "hold" 10 "hold_waiting_user_cmd" 6 "enabled" 5 "faulted" ;
VAL_ 1042 BARRIERS 3 "both" 2 "right" 1 "left" 0 "none" ;
VAL_ 1042 RIGHT_LINE 3 "orange" 2 "double" 1 "solid" 0 "none" ;
VAL_ 1042 LEFT_LINE 3 "orange" 2 "double" 1 "solid" 0 "none" ;
VAL_ 1042 LDA_ALERT 3 "hold with continuous beep" 2 "LDA unavailable" 1 "hold" 0 "none" ;
VAL_ 1556 TURN_SIGNALS 3 "none" 2 "right" 1 "left" ;
CM_ "CHFFR_METRIC 37 STEER_ANGLE STEER_ANGLE 0.36 180";
